AUTOSAR XML (schema 4-2-1)
package /MICROSAR/Issm_swc/DataTypes
  4 x impl type:
    Issm_UserHandleType: range raw 0..255, implementation-data-type=uint8
    Issm_IssHandleType: range raw 0..255, implementation-data-type=uint8
    Issm_IssStateType: compu {0=ISSM_STATE_INACTIVE, 1=ISSM_STATE_PENDING, 2=ISSM_STATE_ACTIVE}, range raw 0..2, implementation-data-type=uint8
    Issm_ActiveUserArrayType: category=ARRAY, sw-calibration-access=READ-ONLY
      element Issm_ActiveUserArrayTypeElement: array-size=1, array-size-semantics=FIXED-SIZE, implementation-data-type=uint32
package /MICROSAR/Issm_swc/Interfaces
  4 x client server interface, all with is-service=true, service-kind=VENDOR-SPECIFIC:
    Issm_IssRequest
      operation ActivateIss: possible-error=Issm_IssRequest/E_NOT_OK
      operation DeactivateIss: possible-error=Issm_IssRequest/E_NOT_OK
      operation GetIssState: possible-error=Issm_IssRequest/E_NOT_OK
        arg issState: type=Issm_IssStateType, direction=OUT
      error E_NOT_OK: error-code=1
    Issm_GetAllActiveIss
      operation GetAllActiveIss: possible-error=Issm_GetAllActiveIss/E_NOT_OK
        arg activeIssField: type=uint32, direction=OUT
      error E_NOT_OK: error-code=1
    Issm_GetAllActiveUsers
      operation GetAllActiveUsers: possible-error=Issm_GetAllActiveUsers/E_NOT_OK
        arg activeUsersField: type=Issm_ActiveUserArrayType, direction=OUT
      error E_NOT_OK: error-code=1
    Issm_IssStateChange
      operation Issm_IssActivation
        arg issID: type=Issm_IssHandleType, direction=IN
      operation Issm_IssDeactivation
        arg issID: type=Issm_IssHandleType, direction=IN
package /MICROSAR/Issm_swc/ComponentTypes
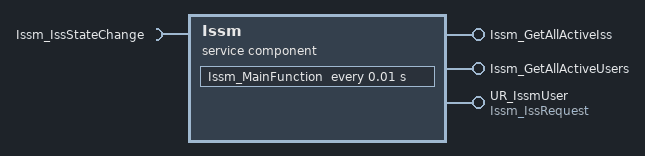
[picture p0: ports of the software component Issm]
  service sw component type Issm: category=SERVICE_COMPONENT
    provide port Issm_GetAllActiveIss: provided-interface=Issm_GetAllActiveIss
    provide port Issm_GetAllActiveUsers: provided-interface=Issm_GetAllActiveUsers
    require port Issm_IssStateChange: required-interface=Issm_IssStateChange
    provide port UR_IssmUser: provided-interface=Issm_IssRequest
    behavior IssmInternalBehavior: handle-termination-and-restart=NO-SUPPORT, included-data-type-set=data-type=[uint32, Issm_UserHandleType, Issm_IssHandleType]
      timing event Timer_Issm_MainFunction: start-on-event=Issm_MainFunction, period=0.01
      5 x operation invoked event:
        OpEventGetAllActiveIss_GetAllActiveIss_Issm_GetAllActiveIss: start-on-event=GetAllActiveIss, operation=Issm_GetAllActiveIss.GetAllActiveIss
        OpEventGetAllActiveUsers_GetAllActiveUsers_Issm_GetAllActiveUsers: start-on-event=GetAllActiveUsers, operation=Issm_GetAllActiveUsers.GetAllActiveUsers
        OpEventActivateIss_ActivateIss_UR_IssmUser: start-on-event=ActivateIss, operation=UR_IssmUser.ActivateIss
        OpEventDeactivateIss_DeactivateIss_UR_IssmUser: start-on-event=DeactivateIss, operation=UR_IssmUser.DeactivateIss
        OpEventGetIssState_GetIssState_UR_IssmUser: start-on-event=GetIssState, operation=UR_IssmUser.GetIssState
      port-api-options:
        enable-take-address=true, indirect-api=false, port=Issm_GetAllActiveIss
        enable-take-address=true, indirect-api=false, port=Issm_GetAllActiveUsers
        enable-take-address=true, indirect-api=false, port=Issm_IssStateChange
        {enable-take-address=true, indirect-api=false, port-defined-argument-value{value=0, value-type=Issm_UserHandleType}, port=UR_IssmUser}
      6 x runnable:
        Issm_MainFunction
          sync call OpServerCallIssm_MainFunction_Issm_IssActivation_Issm_IssStateChange: operation=Issm_IssStateChange.Issm_IssActivation, timeout=0
          sync call OpServerCallIssm_MainFunction_Issm_IssDeactivation_Issm_IssStateChange: operation=Issm_IssStateChange.Issm_IssDeactivation, timeout=0
        GetAllActiveIss: can-be-invoked-concurrently=true, symbol=Issm_GetAllActiveIss
        GetAllActiveUsers: can-be-invoked-concurrently=true, symbol=Issm_GetAllActiveUsers
        ActivateIss: can-be-invoked-concurrently=true, symbol=Issm_ActivateIss
        DeactivateIss: can-be-invoked-concurrently=true, symbol=Issm_DeactivateIss
        GetIssState: can-be-invoked-concurrently=true, symbol=Issm_GetIssState
  swc implementation IssmImplementation: programming-language=C, behavior=IssmInternalBehavior
